# STM32H7B0x register map
File version: 1.3
CPU: CM7 r0p1, little endian, MPU, FPU, 4 interrupt priority bits
Registers are 32-bit, read-write, reset 0x0 unless marked. A register's access mark holds for its fields unless they carry their own. Offsets are from the block's base; [hi:lo] are bit positions; {n}, {i} and the like mark numbered series.

## RCC (part 3 of 3) — Reset and clock control
Base 0x58024400
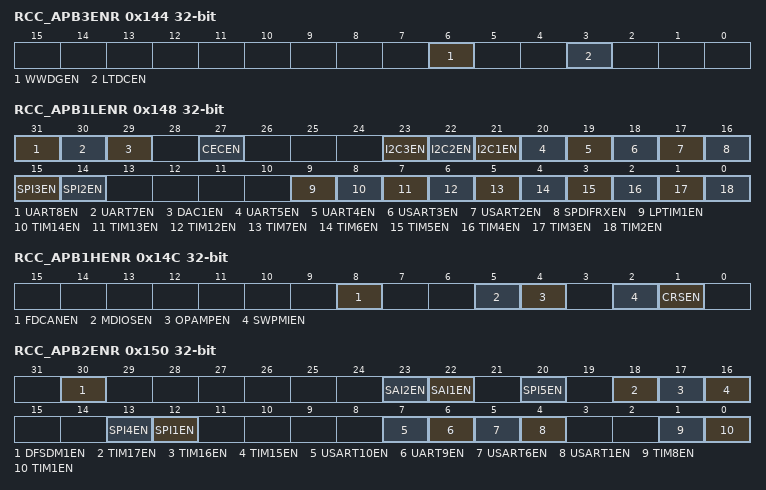
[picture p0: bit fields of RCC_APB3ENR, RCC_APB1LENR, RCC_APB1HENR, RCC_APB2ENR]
0x144 RCC_APB3ENR
  [6] WWDGEN — WWDG clock enable Set by software, and reset by hardware when a system reset occurs. Note that in order to work properly, before enabling the WWDG, the bit WW1RSC must be set to 1.
    0=WWDG peripheral clock disable (default after reset); 1=WWDG peripheral clock enabled
  [3] LTDCEN — LTDC clock enable Provides the clock (ltdc_pclk, ltdc_aclk, ltdc_ker_ck) to the LTDC block. Set and reset by software.
    0=LTDC peripheral clock disabled (default after reset); 1=LTDC peripheral clock provided to the LTDC block
0x148 RCC_APB1LENR
  [31] UART8EN — UART8 peripheral clocks enable Set and reset by software. The peripheral clocks of the UART8 are the kernel clock selected by USART234578SEL and provided to usart_ker_ck input, and the rcc_pclk1 bus interface clock.
    0=UART8 peripheral clocks disabled (default after reset); 1=UART8 peripheral clocks enabled
  [30] UART7EN — UART7 peripheral clocks enable Set and reset by software. The peripheral clocks of the UART7 are the kernel clock selected by USART234578SEL and provided to usart_ker_ck input, and the rcc_pclk1 bus interface clock.
    0=UART7 peripheral clocks disabled (default after reset); 1=UART7 peripheral clocks enabled
  [29] DAC1EN — DAC1 (containing two converters) peripheral clock enable Set and reset by software.
    0=DAC1 peripheral clock disabled (default after reset); 1=DAC1 peripheral clock enabled
  [27] CECEN — HDMI-CEC peripheral clock enable Set and reset by software. The peripheral clocks of the HDMI-CEC are the kernel clock selected by CECSEL and provided to cec_ker_ck input, and the rcc_pclk1 bus interface clock.
    0=HDMI-CEC peripheral clock disabled (default after reset); 1=HDMI-CEC peripheral clock enabled
  [23] I2C3EN — I2C3 peripheral clocks enable Set and reset by software. The peripheral clocks of the I2C3 are the kernel clock selected by I2C123SEL and provided to i2C_ker_ck input, and the rcc_pclk1 bus interface clock.
    0=I2C3 peripheral clocks disabled (default after reset); 1=I2C3 peripheral clocks enabled
  [22] I2C2EN — I2C2 peripheral clocks enable Set and reset by software. The peripheral clocks of the I2C2 are the kernel clock selected by I2C123SEL and provided to i2C_ker_ck input, and the rcc_pclk1 bus interface clock.
    0=I2C2 peripheral clocks disabled (default after reset); 1=I2C2 peripheral clocks enabled
  [21] I2C1EN — I2C1 peripheral clocks enable Set and reset by software. The peripheral clocks of the I2C1 are the kernel clock selected by I2C123SEL and provided to i2C_ker_ck input, and the rcc_pclk1 bus interface clock.
    0=I2C1 peripheral clocks disabled (default after reset); 1=I2C1 peripheral clocks enabled
  [20] UART5EN — UART5 peripheral clocks enable Set and reset by software. The peripheral clocks of the UART5 are the kernel clock selected by USART234578SEL and provided to usart_ker_ck input, and the rcc_pclk1 bus interface clock.
    0=UART5 peripheral clocks disabled (default after reset); 1=UART5 peripheral clocks enabled
  [19] UART4EN — UART4 peripheral clocks enable Set and reset by software. The peripheral clocks of the UART4 are the kernel clock selected by USART234578SEL and provided to usart_ker_ck input, and the rcc_pclk1 bus interface clock.
    0=UART4 peripheral clocks disabled (default after reset); 1=UART4 peripheral clocks enabled
  [18] USART3EN — USART3 peripheral clocks enable Set and reset by software. The peripheral clocks of the USART3 are the kernel clock selected by USART234578SEL and provided to usart_ker_ck input, and the rcc_pclk1 bus interface clock.
    0=USART3 peripheral clocks disabled (default after reset); 1=USART3 peripheral clocks enabled
  [17] USART2EN — USART2peripheral clocks enable Set and reset by software. The peripheral clocks of the USART2 are the kernel clock selected by USART234578SEL and provided to usart_ker_ck input, and the rcc_pclk1 bus interface clock.
    0=USART2 peripheral clocks disabled (default after reset); 1=USART2 peripheral clocks enabled
  [16] SPDIFRXEN — SPDIFRX peripheral clocks enable Set and reset by software. The peripheral clocks of the SPDIFRX are the kernel clock selected by SPDIFRXSEL and provided to spdifrx_ker_ck input, and the rcc_pclk1 bus interface clock.
    0=SPDIFRX peripheral clocks disabled (default after reset); 1=SPDIFRX peripheral clocks enabled
  [15] SPI3EN — SPI3 peripheral clocks enable Set and reset by software. The peripheral clocks of the SPI3 are the kernel clock selected by I2S123SRC and provided to spi_ker_ck input, and the rcc_pclk1 bus interface clock.
    0=SPI3 peripheral clocks disabled (default after reset); 1=SPI3 peripheral clocks enabled
  [14] SPI2EN — SPI2 peripheral clocks enable Set and reset by software. The peripheral clocks of the SPI2 are the kernel clock selected by I2S123SRC and provided to spi_ker_ck input, and the rcc_pclk1 bus interface clock.
    0=SPI2 peripheral clocks disabled (default after reset); 1=SPI2 peripheral clocks enabled
  [9] LPTIM1EN — LPTIM1 peripheral clocks enable Set and reset by software. The peripheral clocks of the LPTIM1 are the kernel clock selected by LPTIM1SEL and provided to lptim_ker_ck input, and the rcc_pclk1 bus interface clock.
    0=LPTIM1 peripheral clocks disabled (default after reset); 1=LPTIM1 peripheral clocks enabled
  [8] TIM14EN — TIM14 peripheral clock enable Set and reset by software.
    0=TIM14 peripheral clock disabled (default after reset); 1=TIM14 peripheral clock enabled
  [7] TIM13EN — TIM13 peripheral clock enable Set and reset by software.
    0=TIM13 peripheral clock disabled (default after reset); 1=TIM13 peripheral clock enabled
  [6] TIM12EN — TIM12 peripheral clock enable Set and reset by software.
    0=TIM12 peripheral clock disabled (default after reset); 1=TIM12 peripheral clock enabled
  [5] TIM7EN — TIM7 peripheral clock enable Set and reset by software.
    0=TIM7 peripheral clock disabled (default after reset); 1=TIM7 peripheral clock enabled
  [4] TIM6EN — TIM6 peripheral clock enable Set and reset by software.
    0=TIM6 peripheral clock disabled (default after reset); 1=TIM6 peripheral clock enabled
  [3] TIM5EN — TIM5 peripheral clock enable Set and reset by software.
    0=TIM5 peripheral clock disabled (default after reset); 1=TIM5 peripheral clock enabled
  [2] TIM4EN — TIM4 peripheral clock enable Set and reset by software.
    0=TIM4 peripheral clock disable (default after reset); 1=TIM4 peripheral clock enabled
  [1] TIM3EN — TIM3 peripheral clock enable Set and reset by software.
    0=TIM3 peripheral clock disabled (default after reset); 1=TIM3 peripheral clock enabled
  [0] TIM2EN — TIM2 peripheral clock enable Set and reset by software.
    0=TIM2 peripheral clock disabled (default after reset); 1=TIM2 peripheral clock enabled
0x14C RCC_APB1HENR
  [8] FDCANEN — FDCAN peripheral clocks enable Set and reset by software. The peripheral clocks of the FDCAN are the kernel clock selected by FDCANSEL and provided to fdcan_ker_ck input, and the rcc_pclk1 bus interface clock.
    0=FDCAN peripheral clocks disabled (default after reset); 1=FDCAN peripheral clocks enabled:
  [5] MDIOSEN — MDIOS peripheral clock enable Set and reset by software.
    0=MDIOS peripheral clock disabled (default after reset); 1=MDIOS peripheral clock enabled
  [4] OPAMPEN — OPAMP peripheral clock enable Set and reset by software.
    0=OPAMP peripheral clock disabled (default after reset); 1=OPAMP peripheral clock enabled
  [2] SWPMIEN — SWPMI peripheral clocks enable Set and reset by software.
    0=SWPMI peripheral clocks disabled (default after reset); 1=SWPMI peripheral clocks enabled:
  [1] CRSEN — clock recovery system peripheral clock enable Set and reset by software.
    0=CRS peripheral clock disabled (default after reset); 1=CRS peripheral clock enabled
0x150 RCC_APB2ENR
  [30] DFSDM1EN — DFSDM1 peripheral clocks enable Set and reset by software. DFSDM1 peripheral clocks are the kernel clocks selected by SAI1SEL and DFSDM1SEL and provided to Aclk and clk inputs respectively,
    0=DFSDM1 peripheral clocks disabled (default after reset); 1=DFSDM1 peripheral clocks enabled
  [23] SAI2EN — SAI2 peripheral clocks enable Set and reset by software. The peripheral clocks of the SAI2 are the kernel clock selected by SAI2SEL and provided to sai_a_ker_ck and sai_b_ker_ck inputs, and the rcc_pclk2 bus interface clock.
    0=SAI2 peripheral clocks disabled (default after reset); 1=SAI2 peripheral clocks enabled
  [22] SAI1EN — SAI1 peripheral clocks enable Set and reset by software. The peripheral clocks of the SAI1 are: the kernel clock selected by SAI1SEL and provided to sai_a_ker_ck and sai_b_ker_ck inputs, and the rcc_pclk2 bus interface clock.
    0=SAI1 peripheral clocks disabled (default after reset); 1=SAI1 peripheral clocks enabled:
  [20] SPI5EN — SPI5 peripheral clocks enable Set and reset by software. The peripheral clocks of the SPI5 are the kernel clock selected by SPI45SEL and provided to spi_ker_ck input, and the rcc_pclk2 bus interface clock.
    0=SPI5 peripheral clocks disabled (default after reset); 1=SPI5 peripheral clocks enabled:
  [18] TIM17EN — TIM17 peripheral clock enable Set and reset by software.
    0=TIM17 peripheral clock disabled (default after reset); 1=TIM17 peripheral clock enabled
  [17] TIM16EN — TIM16 peripheral clock enable Set and reset by software.
    0=TIM16 peripheral clock disabled (default after reset); 1=TIM16 peripheral clock enabled
  [16] TIM15EN — TIM15 peripheral clock enable Set and reset by software.
    0=TIM15 peripheral clock disabled (default after reset); 1=TIM15 peripheral clock enabled
  [13] SPI4EN — SPI4 Peripheral Clocks Enable Set and reset by software. The peripheral clocks of the SPI4 are: the kernel clock selected by SPI45SEL and provided to spi_ker_ck input, and the rcc_pclk2 bus interface clock.
    0=SPI4 peripheral clocks disabled (default after reset); 1=SPI4 peripheral clocks enabled:
  [12] SPI1EN — SPI1 Peripheral Clocks Enable Set and reset by software. The peripheral clocks of the SPI1 are: the kernel clock selected by I2S123SRC and provided to spi_ker_ck input, and the rcc_pclk2 bus interface clock.
    0=SPI1 peripheral clocks disabled (default after reset); 1=SPI1 peripheral clocks enabled:
  [7] USART10EN — USART10 peripheral clocks enable Set and reset by software. The peripheral clocks of the USART10 are the kernel clock selected by USART16910SEL and provided to UCKL input, and the rcc_pclk2 bus interface clock.
    0=USART10 peripheral clocks disabled (default after reset); 1=USART10 peripheral clocks enabled:
  [6] UART9EN — UART9 peripheral clocks enable Set and reset by software. The peripheral clocks of the UART9 are the kernel clock selected by USART16910SEL and provided to UCKL input, and the rcc_pclk2 bus interface clock.
    0=UART9 peripheral clocks disabled (default after reset); 1=UART9 peripheral clocks enabled:
  [5] USART6EN — USART6 peripheral clocks enable Set and reset by software. The peripheral clocks of the USART6 are the kernel clock selected by USART16910SEL and provided to UCKL input, and the rcc_pclk2 bus interface clock.
    0=USART6 peripheral clocks disabled (default after reset); 1=USART6 peripheral clocks enabled:
  [4] USART1EN — USART1 peripheral clocks enable Set and reset by software. The peripheral clocks of the USART1 are the kernel clock selected by USART16910SEL and provided to UCKL input, and the rcc_pclk2 bus interface clock.
    0=USART1 peripheral clocks disabled (default after reset); 1=USART1 peripheral clocks enabled:
  [1] TIM8EN — TIM8 peripheral clock enable Set and reset by software.
    0=TIM8 peripheral clock disabled (default after reset); 1=TIM8 peripheral clock enabled
  [0] TIM1EN — TIM1 peripheral clock enable Set and reset by software.
    0=TIM1 peripheral clock disabled (default after reset); 1=TIM1 peripheral clock enabled
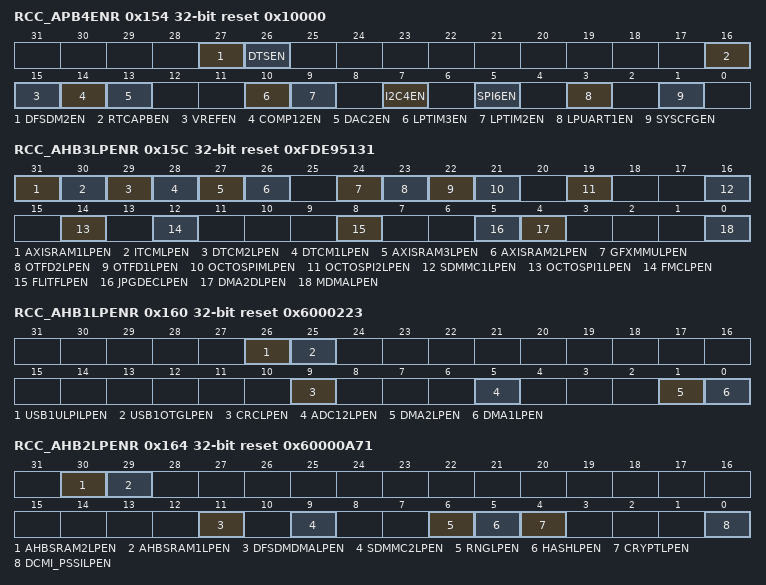
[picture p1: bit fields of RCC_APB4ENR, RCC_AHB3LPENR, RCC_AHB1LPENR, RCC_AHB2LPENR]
0x154 RCC_APB4ENR reset 0x10000
  [27] DFSDM2EN — DFSDM2peripheral clock enable Set and reset by software.
    0=DFSDM2peripheral peripheral clock disabled (default after reset); 1=DFSDM2peripheral peripheral clock enabled
  [26] DTSEN — Digital temperature sensor peripheral clock enable Set and reset by software.
    0=DTS peripheral clock disabled (default after reset); 1=DTS peripheral clock enabled
  [16] RTCAPBEN — RTC APB clock enable Set and reset by software.
    0=The register clock interface of the RTC (APB) is disabled; 1=The register clock interface of the RTC (APB) is enabled (default after reset)
  [15] VREFEN — VREF peripheral clock enable Set and reset by software.
    0=VREF peripheral clock disabled (default after reset); 1=VREF peripheral clock enabled
  [14] COMP12EN — COMP1 and 2 peripheral clock enable Set and reset by software.
    0=COMP1 and 2 peripheral clock disabled (default after reset); 1=COMP1 and 2 peripheral clock enabled
  [13] DAC2EN — DAC2 (containing one converter) peripheral clock enable Set and reset by software.
    0=DAC2 peripheral clock disabled (default after reset); 1=DAC2 peripheral clock enabled
  [10] LPTIM3EN — LPTIM3 peripheral clocks enable Set and reset by software. The peripheral clocks of the LPTIM3 are the kernel clock selected by LPTIM345SEL and provided to lptim_ker_ck input, and the rcc_pclk4 bus interface clock.
    0=LPTIM3 peripheral clocks disabled (default after reset); 1=LPTIM3 peripheral clocks enabled
  [9] LPTIM2EN — LPTIM2 peripheral clocks enable Set and reset by software. The peripheral clocks of the LPTIM2 are the kernel clock selected by LPTIM2SEL and provided to lptim_ker_ck input, and the rcc_pclk4 bus interface clock.
    0=LPTIM2 peripheral clocks disabled (default after reset); 1=LPTIM2 peripheral clocks enabled
  [7] I2C4EN — I2C4 peripheral clocks enable Set and reset by software. The peripheral clocks of the I2C4 are the kernel clock selected by I2C4SEL and provided to i2C_ker_ck input, and the rcc_pclk4 bus interface clock.
    0=I2C4 peripheral clocks disabled (default after reset); 1=I2C4 peripheral clocks enabled
  [5] SPI6EN — SPI6 peripheral clocks enable Set and reset by software. The peripheral clocks of the SPI6 are the kernel clock selected by SPI6SEL and provided to spi_ker_ck input, and the rcc_pclk4 bus interface clock.
    0=SPI6 peripheral clocks disabled (default after reset); 1=SPI6 peripheral clocks enabled
  [3] LPUART1EN — LPUART1 peripheral clocks enable Set and reset by software. The peripheral clocks of the LPUART1 are the kernel clock selected by LPUART1SEL and provided to lpuart_ker_ck input, and the rcc_pclk4 bus interface clock.
    0=LPUART1 peripheral clocks disabled (default after reset); 1=LPUART1 peripheral clocks enabled
  [1] SYSCFGEN — SYSCFG peripheral clock enable Set and reset by software.
    0=SYSCFG peripheral clock disabled (default after reset); 1=SYSCFG peripheral clock enabled
0x15C RCC_AHB3LPENR reset 0xFDE95131
  [31] AXISRAM1LPEN — AXISRAM1 block clock enable during CSleep mode Set and reset by software.
    0=AXISRAM1 interface clock disabled during CSleep mode; 1=AXISRAM1 interface clock enabled during CSleep mode (default after reset)
  [30] ITCMLPEN — ITCM block clock enable during CSleep mode Set and reset by software.
    0=ITCM interface clock disabled during CSleep mode; 1=ITCM interface clock enabled during CSleep mode (default after reset)
  [29] DTCM2LPEN — DTCM2 block clock enable during CSleep mode Set and reset by software.
    0=DTCM2 interface clock disabled during CSleep mode; 1=DTCM2 interface clock enabled during CSleep mode (default after reset)
  [28] DTCM1LPEN — DTCM1 block clock enable during CSleep mode Set and reset by software.
    0=DTCM1 interface clock disabled during CSleep mode; 1=DTCM1 interface clock enabled during CSleep mode (default after reset)
  [27] AXISRAM3LPEN — AXISRAM3 block clock enable during CSleep mode Set and reset by software.
    0=AXISRAM3 interface clock disabled during CSleep mode; 1=AXISRAM3 interface clock enabled during CSleep mode (default after reset)
  [26] AXISRAM2LPEN — AXISRAM2 block clock enable during CSleep mode Set and reset by software.
    0=AXISRAM2 interface clock disabled during CSleep mode; 1=AXISRAM2 interface clock enabled during CSleep mode (default after reset)
  [24] GFXMMULPEN — GFXMMU block clock enable during CSleep mode Set and reset by software.
    0=GFXMMU interface clock disabled during CSleep mode; 1=GFXMMU interface clock enabled during CSleep mode (default after reset)
  [23] OTFD2LPEN — OTFD2 block clock enable during CSleep mode Set and reset by software.
    0=OTFD2 interface clock disabled during CSleep mode; 1=OTFD2 interface clock enabled during CSleep mode (default after reset)
  [22] OTFD1LPEN — OTFD1 block clock enable during CSleep mode Set and reset by software.
    0=OTFD1 interface clock disabled during CSleep mode; 1=OTFD1 interface clock enabled during CSleep mode (default after reset)
  [21] OCTOSPIMLPEN — OCTOSPIM block clock enable during CSleep mode Set and reset by software.
    0=OCTOSPIM interface clock disabled during CSleep mode; 1=OCTOSPIM interface clock enabled during CSleep mode (default after reset)
  [19] OCTOSPI2LPEN — OCTOSPI2 and OCTOSPI2 delay clock enable during CSleep mode Set and reset by software.
    0=OCTOSPI2 and OCTOSPI2 delay clock disabled during CSleep mode; 1=OCTOSPI2 and OCTOSPI2 delay clock enabled during CSleep mode (default after reset)
  [16] SDMMC1LPEN — SDMMC1 and SDMMC1 delay clock enable during CSleep mode Set and reset by software.
    0=SDMMC1 and SDMMC1 delay clock disabled during CSleep mode; 1=SDMMC1 and SDMMC1 delay clock enabled during CSleep mode (default after reset)
  [14] OCTOSPI1LPEN — OCTOSPI1 and OCTOSPI1 delay clock enable during CSleep mode Set and reset by software.
    0=OCTOSPI1 and OCTOSPI1 delay clock disabled during CSleep mode; 1=OCTOSPI1 and OCTOSPI1 delay clock enabled during CSleep mode (default after reset)
  [12] FMCLPEN — FMC peripheral clocks enable during CSleep mode Set and reset by software. The peripheral clocks of the FMC are the kernel clock selected by FMCSEL and provided to fmc_ker_ck input, and the rcc_hclk3 bus interface clock.
    0=FMC peripheral clocks disabled during CSleep mode; 1=FMC peripheral clocks enabled during CSleep mode (default after reset):
  [8] FLITFLPEN — FLITF clock enable during CSleep mode Set and reset by software.
    0=FLITF clock disabled during CSleep mode; 1=FLITF clock enabled during CSleep mode (default after reset)
  [5] JPGDECLPEN — JPGDEC clock enable during CSleep mode Set and reset by software.
    0=JPGDEC peripheral clock disabled during CSleep mode; 1=JPGDEC peripheral clock enabled during CSleep mode (default after reset)
  [4] DMA2DLPEN — DMA2D clock enable during CSleep mode Set and reset by software.
    0=DMA2D peripheral clock disabled during CSleep mode; 1=DMA2D peripheral clock enabled during CSleep mode (default after reset)
  [0] MDMALPEN — MDMA clock enable during CSleep mode Set and reset by software.
    0=MDMA peripheral clock disabled during CSleep mode; 1=MDMA peripheral clock enabled during CSleep mode (default after reset)
0x160 RCC_AHB1LPENR reset 0x6000223
  [26] USB1ULPILPEN — USB_PHY1 clock enable during CSleep mode Set and reset by software.
    0=USB_PHY1 peripheral clock disabled during CSleep mode; 1=USB_PHY1 peripheral clock enabled during CSleep mode (default after reset)
  [25] USB1OTGLPEN — USB1OTG peripheral clock enable during CSleep mode Set and reset by software. The peripheral clocks of the USB1OTG are the kernel clock selected by USBSEL and the rcc_hclk1 bus interface clock.
    0=USB1OTG peripheral clock disabled during CSleep mode; 1=USB1OTG peripheral clock enabled during CSleep mode (default after reset)
  [9] CRCLPEN — CRC peripheral clock enable during CSleep mode Set and reset by software.
    0=CRC peripheral clock disabled during CSleep mode; 1=CRC peripheral clock enabled during CSleep mode (default after reset)
  [5] ADC12LPEN — ADC1 and 2 peripheral clocks enable during CSleep mode Set and reset by software. The peripheral clocks of the ADC1 and 2 are the kernel clock selected by ADCSEL and provided to adc_ker_ck input, and the rcc_hclk1 bus interface clock.
    0=ADC1 and 2 peripheral clocks disabled during CSleep mode; 1=ADC1 and 2 peripheral clocks enabled during CSleep mode (default after reset)
  [1] DMA2LPEN — DMA2 clock enable during CSleep mode Set and reset by software.
    0=DMA2 clock disabled during CSleep mode; 1=DMA2 clock enabled during CSleep mode (default after reset)
  [0] DMA1LPEN — DMA1 clock enable during CSleep mode Set and reset by software.
    0=DMA1 clock disabled during CSleep mode; 1=DMA1 clock enabled during CSleep mode (default after reset)
0x164 RCC_AHB2LPENR reset 0x60000A71
  [30] AHBSRAM2LPEN — AHBSRAM2 clock enable during CSleep mode Set and reset by software.
    0=AHBSRAM2 clock disabled during CSleep mode; 1=AHBSRAM2 clock enabled during CSleep mode (default after reset)
  [29] AHBSRAM1LPEN — AHBSRAM1 clock enable during CSleep mode Set and reset by software.
    0=AHBSRAM1 clock disabled during CSleep mode; 1=AHBSRAM1 clock enabled during CSleep mode (default after reset)
  [11] DFSDMDMALPEN — DFSDMDMA clock enable during CSleep mode Set and reset by software.
    0=DFSDMDMA clock disabled during CSleep mode; 1=DFSDMDMA clock enabled during CSleep mode (default after reset)
  [9] SDMMC2LPEN — SDMMC2 and SDMMC2 delay clock enable during CSleep mode Set and reset by software.
    0=SDMMC2 and SDMMC2 delay clock disabled during CSleep mode; 1=SDMMC2 and SDMMC2 delay clock enabled during CSleep mode (default after reset)
  [6] RNGLPEN — RNG peripheral clock enable during CSleep mode Set and reset by software. The peripheral clocks of the RNG are the kernel clock selected by RNGSEL and provided to rng_clk input, and the rcc_hclk2 bus interface clock.
    0=RNG peripheral clocks disabled during CSleep mode; 1=RNG peripheral clock enabled during CSleep mode (default after reset)
  [5] HASHLPEN — HASH peripheral clock enable during CSleep mode Set and reset by software.
    0=HASH peripheral clock disabled during CSleep mode; 1=HASH peripheral clock enabled during CSleep mode (default after reset)
  [4] CRYPTLPEN — CRYPT peripheral clock enable during CSleep mode Set and reset by software.
    0=CRYPT peripheral clock disabled during CSleep mode; 1=CRYPT peripheral clock enabled during CSleep mode (default after reset)
  [0] DCMI_PSSILPEN — digital camera interface peripheral clock enable during CSleep mode (DCMI or PSSI depending which IP is active) Set and reset by software.
    0=DCMI/PSSI peripheral clock disabled during CSleep mode; 1=DCMI/PSSI peripheral clock enabled during CSleep mode (default after reset)
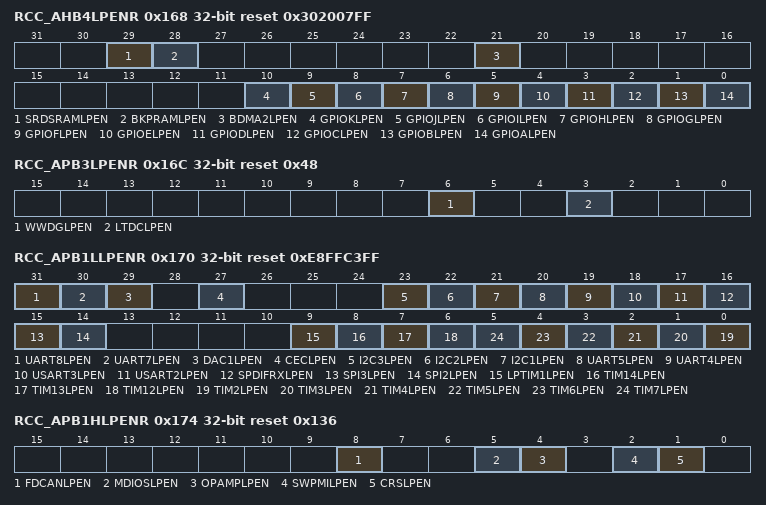
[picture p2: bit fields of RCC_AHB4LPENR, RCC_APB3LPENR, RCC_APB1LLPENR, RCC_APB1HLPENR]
0x168 RCC_AHB4LPENR reset 0x302007FF
  [29] SRDSRAMLPEN — SmartRun domain SRAM clock enable during CSleep mode Set and reset by software.
    0=SRDSRAM clock disabled during CSleep mode; 1=SRDSRAM clock enabled during CSleep mode (default after reset)
  [28] BKPRAMLPEN — Backup RAM clock enable during CSleep mode Set and reset by software.
    0=Backup RAM clock disabled during CSleep mode; 1=Backup RAM clock enabled during CSleep mode (default after reset)
  [21] BDMA2LPEN — SmartRun domain DMA and DMAMUX clock enable during CSleep mode Set and reset by software.
    0=BDMA2 and DMAMUX2 clock disabled during CSleep mode; 1=BDMA2 and DMAMUX2 clock enabled during CSleep mode (default after reset)
  [10] GPIOKLPEN — GPIOK peripheral clock enable during CSleep mode Set and reset by software.
    0=GPIOK peripheral clock disabled during CSleep mode; 1=GPIOK peripheral clock enabled during CSleep mode (default after reset)
  [9] GPIOJLPEN — GPIOJ peripheral clock enable during CSleep mode Set and reset by software.
    0=GPIOJ peripheral clock disabled during CSleep mode; 1=GPIOJ peripheral clock enabled during CSleep mode (default after reset)
  [8] GPIOILPEN — GPIOI peripheral clock enable during CSleep mode Set and reset by software.
    0=GPIOI peripheral clock disabled during CSleep mode; 1=GPIOI peripheral clock enabled during CSleep mode (default after reset)
  [7] GPIOHLPEN — GPIOH peripheral clock enable during CSleep mode Set and reset by software.
    0=GPIOH peripheral clock disabled during CSleep mode; 1=GPIOH peripheral clock enabled during CSleep mode (default after reset)
  [6] GPIOGLPEN — GPIOG peripheral clock enable during CSleep mode Set and reset by software.
    0=GPIOG peripheral clock disabled during CSleep mode; 1=GPIOG peripheral clock enabled during CSleep mode (default after reset)
  [5] GPIOFLPEN — GPIOF peripheral clock enable during CSleep mode Set and reset by software.
    0=GPIOF peripheral clock disabled during CSleep mode; 1=GPIOF peripheral clock enabled during CSleep mode (default after reset)
  [4] GPIOELPEN — GPIOE peripheral clock enable during CSleep mode Set and reset by software.
    0=GPIOE peripheral clock disabled during CSleep mode; 1=GPIOE peripheral clock enabled during CSleep mode (default after reset)
  [3] GPIODLPEN — GPIOD peripheral clock enable during CSleep mode Set and reset by software.
    0=GPIOD peripheral clock disabled during CSleep mode; 1=GPIOD peripheral clock enabled during CSleep mode (default after reset)
  [2] GPIOCLPEN — GPIOC peripheral clock enable during CSleep mode Set and reset by software.
    0=GPIOC peripheral clock disabled during CSleep mode; 1=GPIOC peripheral clock enabled during CSleep mode (default after reset)
  [1] GPIOBLPEN — GPIOB peripheral clock enable during CSleep mode Set and reset by software.
    0=GPIOB peripheral clock disabled during CSleep mode; 1=GPIOB peripheral clock enabled during CSleep mode (default after reset)
  [0] GPIOALPEN — GPIOA peripheral clock enable during CSleep mode Set and reset by software.
    0=GPIOA peripheral clock disabled during CSleep mode; 1=GPIOA peripheral clock enabled during CSleep mode (default after reset)
0x16C RCC_APB3LPENR reset 0x48
  [6] WWDGLPEN — WWDG clock enable during CSleep mode Set and reset by software.
    0=WWDG clock disable during CSleep mode; 1=WWDG clock enabled during CSleep mode (default after reset)
  [3] LTDCLPEN — LTDC peripheral clock enable during CSleep mode Set and reset by software. The LTDC peripheral clocks are the kernel clock provided to ltdc_ker_ck input and the rcc_pclk3 bus interface clock.
    0=LTDC clock disabled during CSleep mode; 1=LTDC clock provided to the LTDC during CSleep mode (default after reset)
0x170 RCC_APB1LLPENR reset 0xE8FFC3FF
  [31] UART8LPEN — UART8 peripheral clocks enable during CSleep mode Set and reset by software. The peripheral clocks of the UART8 are the kernel clock selected by USART234578SEL and provided to usart_ker_ck input, and the rcc_pclk1 bus interface clock.
    0=UART8 peripheral clocks disabled during CSleep mode; 1=UART8 peripheral clocks enabled during CSleep mode (default after reset):
  [30] UART7LPEN — UART7 peripheral clocks enable during CSleep mode Set and reset by software. The peripheral clocks of the UART7 are the kernel clock selected by USART234578SEL and provided to usart_ker_ck input, and the rcc_pclk1 bus interface clock.
    0=UART7 peripheral clocks disabled during CSleep mode; 1=UART7 peripheral clocks enabled during CSleep mode (default after reset):
  [29] DAC1LPEN — DAC1 (containing two converters) peripheral clock enable during CSleep mode Set and reset by software.
    0=DAC1 peripheral clock disabled during CSleep mode; 1=DAC1 peripheral clock enabled during CSleep mode (default after reset)
  [27] CECLPEN — HDMI-CEC peripheral clocks enable during CSleep mode Set and reset by software. The peripheral clocks of the HDMI-CEC are the kernel clock selected by CECSEL and provided to cec_ker_ck input, and the rcc_pclk1 bus interface clock.
    0=HDMI-CEC peripheral clocks disabled during CSleep mode; 1=HDMI-CEC peripheral clocks enabled during CSleep mode (default after reset)
  [23] I2C3LPEN — I2C3 peripheral clocks enable during CSleep mode Set and reset by software. The peripheral clocks of the I2C3 are the kernel clock selected by I2C123SEL and provided to i2C_ker_ck input, and the rcc_pclk1 bus interface clock.
    0=I2C3 peripheral clocks disabled during CSleep mode; 1=I2C3 peripheral clocks enabled during CSleep mode (default after reset):
  [22] I2C2LPEN — I2C2 peripheral clocks enable during CSleep mode Set and reset by software. The peripheral clocks of the I2C2 are the kernel clock selected by I2C123SEL and provided to i2C_ker_ck input, and the rcc_pclk1 bus interface clock.
    0=I2C2 peripheral clocks disabled during CSleep mode; 1=I2C2 peripheral clocks enabled during CSleep mode (default after reset):
  [21] I2C1LPEN — I2C1 peripheral clocks enable during CSleep mode Set and reset by software. The peripheral clocks of the I2C1 are the kernel clock selected by I2C123SEL and provided to i2C_ker_ck input, and the rcc_pclk1 bus interface clock.
    0=I2C1 peripheral clocks disabled during CSleep mode; 1=I2C1 peripheral clocks enabled during CSleep mode (default after reset):
  [20] UART5LPEN — UART5 peripheral clocks enable during CSleep mode Set and reset by software. The peripheral clocks of the UART5 are the kernel clock selected by USART234578SEL and provided to usart_ker_ck input, and the rcc_pclk1 bus interface clock.
    0=UART5 peripheral clocks disabled during CSleep mode; 1=UART5 peripheral clocks enabled during CSleep mode (default after reset)
  [19] UART4LPEN — UART4 peripheral clocks enable during CSleep mode Set and reset by software. The peripheral clocks of the UART4 are the kernel clock selected by USART234578SEL and provided to usart_ker_ck input, and the rcc_pclk1 bus interface clock.
    0=UART4 peripheral clocks disabled during CSleep mode; 1=UART4 peripheral clocks enabled during CSleep mode (default after reset)
  [18] USART3LPEN — USART3 peripheral clocks enable during CSleep mode Set and reset by software. The peripheral clocks of the USART3 are the kernel clock selected by USART234578SEL and provided to usart_ker_ck input, and the rcc_pclk1 bus interface clock.
    0=USART3 peripheral clocks disabled during CSleep mode; 1=USART3 peripheral clocks enabled during CSleep mode (default after reset):
  [17] USART2LPEN — USART2 peripheral clocks enable during CSleep mode Set and reset by software. The peripheral clocks of the USART2 are the kernel clock selected by USART234578SEL and provided to usart_ker_ck input, and the rcc_pclk1 bus interface clock.
    0=USART2 peripheral clocks disabled during CSleep mode; 1=USART2 peripheral clocks enabled during CSleep mode (default after reset)
  [16] SPDIFRXLPEN — SPDIFRX peripheral clocks enable during CSleep mode Set and reset by software. The peripheral clocks of the SPDIFRX are: the kernel clock selected by SPDIFRXSEL and provided to spdifrx_ker_ck input, and the rcc_pclk1 bus interface clock.
    0=SPDIFRX peripheral clocks disabled during CSleep mode; 1=SPDIFRX peripheral clocks enabled during CSleep mode (default after reset)
  [15] SPI3LPEN — SPI3 peripheral clocks enable during CSleep mode Set and reset by software. The peripheral clocks of the SPI3 are the kernel clock selected by I2S123SRC and provided to spi_ker_ck input, and the rcc_pclk1 bus interface clock.
    0=SPI3 peripheral clocks disabled during CSleep mode; 1=SPI3 peripheral clocks enabled during CSleep mode (default after reset)
  [14] SPI2LPEN — SPI2 peripheral clocks enable during CSleep mode Set and reset by software. The peripheral clocks of the SPI2 are the kernel clock selected by I2S123SRC and provided to spi_ker_ck input, and the rcc_pclk1 bus interface clock.
    0=SPI2 peripheral clocks disabled during CSleep mode; 1=SPI2 peripheral clocks enabled during CSleep mode (default after reset)
  [9] LPTIM1LPEN — LPTIM1 peripheral clocks enable during CSleep mode Set and reset by software. The peripheral clocks of the LPTIM1 are the kernel clock selected by LPTIM1SEL and provided to lptim_ker_ck input, and the rcc_pclk1 bus interface clock.
    0=LPTIM1 peripheral clocks disabled during CSleep mode; 1=LPTIM1 peripheral clocks enabled during CSleep mode (default after reset)
  [8] TIM14LPEN — TIM14 peripheral clock enable during CSleep mode Set and reset by software.
    0=TIM14 peripheral clock disabled during CSleep mode; 1=TIM14 peripheral clock enabled during CSleep mode (default after reset)
  [7] TIM13LPEN — TIM13 peripheral clock enable during CSleep mode Set and reset by software.
    0=TIM13 peripheral clock disabled during CSleep mode; 1=TIM13 peripheral clock enabled during CSleep mode (default after reset)
  [6] TIM12LPEN — TIM12 peripheral clock enable during CSleep mode Set and reset by software.
    0=TIM12 peripheral clock disabled during CSleep mode; 1=TIM12 peripheral clock enabled during CSleep mode (default after reset)
  [n-2] TIM{n}LPEN (n=2..7) — TIM{n} peripheral clock enable during CSleep mode Set and reset by software.
    0=TIM{n} peripheral clock disabled during CSleep mode; 1=TIM{n} peripheral clock enabled during CSleep mode (default after reset)
0x174 RCC_APB1HLPENR reset 0x136
  [8] FDCANLPEN — FDCAN peripheral clocks enable during CSleep mode Set and reset by software. The peripheral clocks of the FDCAN are: the kernel clock selected by FDCANSEL and provided to fdcan_clk input, and the rcc_pclk1 bus interface clock.
    0=FDCAN peripheral clocks disabled during CSleep mode; 1=FDCAN peripheral clocks enabled during CSleep mode (default after reset)
  [5] MDIOSLPEN — MDIOS peripheral clock enable during CSleep mode Set and reset by software.
    0=MDIOS peripheral clock disabled during CSleep mode; 1=MDIOS peripheral clock enabled during CSleep mode (default after reset)
  [4] OPAMPLPEN — OPAMP peripheral clock enable during CSleep mode Set and reset by software.
    0=OPAMP peripheral clock disabled during CSleep mode; 1=OPAMP peripheral clock enabled during CSleep mode (default after reset)
  [2] SWPMILPEN — SWPMI peripheral clocks enable during CSleep mode Set and reset by software. The peripheral clocks of the SWPMI are the kernel clock selected by SWPMISEL and provided to swpmi_ker_ck input, and the rcc_pclk1 bus interface clock.
    0=SWPMI peripheral clocks disabled during CSleep mode; 1=SWPMI peripheral clocks enabled during CSleep mode (default after reset)
  [1] CRSLPEN — clock recovery system peripheral clock enable during CSleep mode Set and reset by software.
    0=CRS peripheral clock disabled during CSleep mode; 1=CRS peripheral clock enabled during CSleep mode (default after reset)
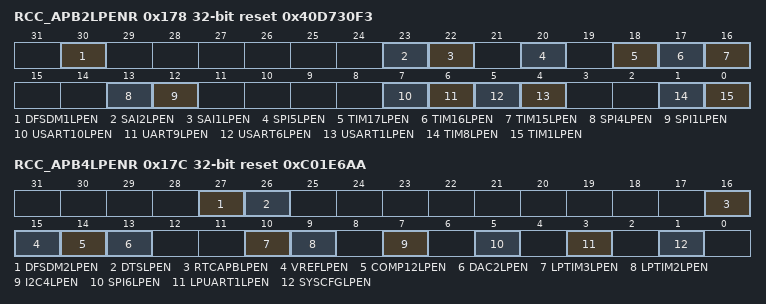
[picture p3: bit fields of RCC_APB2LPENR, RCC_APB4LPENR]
0x178 RCC_APB2LPENR reset 0x40D730F3
  [30] DFSDM1LPEN — DFSDM1 peripheral clocks enable during CSleep mode Set and reset by software. DFSDM1 peripheral clocks are the kernel clocks selected by SAI1SEL and DFSDM1SEL and provided to Aclk and clk inputs respectively, and the rcc_pclk2 bus interface clock.
    0=DFSDM1 peripheral clocks disabled during CSleep mode; 1=DFSDM1 peripheral clocks enabled during CSleep mode (default after reset)
  [23] SAI2LPEN — SAI2 peripheral clocks enable during CSleep mode Set and reset by software. The peripheral clocks of the SAI2 are the kernel clock selected by SAI23EL and provided to sai_a_ker_ck and sai_b_ker_ck inputs, and the rcc_pclk2 bus interface clock.
    0=SAI2 peripheral clocks disabled during CSleep mode; 1=SAI2 peripheral clocks enabled during CSleep mode (default after reset)
  [22] SAI1LPEN — SAI1 peripheral clocks enable during CSleep mode Set and reset by software. The peripheral clocks of the SAI1 are: the kernel clock selected by SAI1SEL and provided to sai_a_ker_ck and sai_b_ker_ck inputs, and the rcc_pclk2 bus interface clock.
    0=SAI1 peripheral clocks disabled during CSleep mode; 1=SAI1 peripheral clocks enabled during CSleep mode (default after reset)
  [20] SPI5LPEN — SPI5 peripheral clocks enable during CSleep mode Set and reset by software. The peripheral clocks of the SPI5 are the kernel clock selected by SPI45SEL and provided to spi_ker_ck input, and the rcc_pclk2 bus interface clock.
    0=SPI5 peripheral clocks disabled during CSleep mode; 1=SPI5 peripheral clocks enabled during CSleep mode (default after reset)
  [18] TIM17LPEN — TIM17 peripheral clock enable during CSleep mode Set and reset by software.
    0=TIM17 peripheral clock disabled during CSleep mode; 1=TIM17 peripheral clock enabled during CSleep mode (default after reset)
  [17] TIM16LPEN — TIM16 peripheral clock enable during CSleep mode Set and reset by software.
    0=TIM16 peripheral clock disabled during CSleep mode; 1=TIM16 peripheral clock enabled during CSleep mode (default after reset)
  [16] TIM15LPEN — TIM15 peripheral clock enable during CSleep mode Set and reset by software.
    0=TIM15 peripheral clock disabled during CSleep mode; 1=TIM15 peripheral clock enabled during CSleep mode (default after reset)
  [13] SPI4LPEN — SPI4 peripheral clock enable during CSleep mode Set and reset by software. The peripheral clocks of the SPI4 are: the kernel clock selected by SPI45SEL and provided to spi_ker_ck input, and the rcc_pclk2 bus interface clock.
    0=SPI4 peripheral clocks disabled during CSleep mode; 1=SPI4 peripheral clocks enabled during CSleep mode (default after reset)
  [12] SPI1LPEN — SPI1 peripheral clock enable during CSleep mode Set and reset by software. The peripheral clocks of the SPI1 are: the kernel clock selected by I2S123SRC and provided to spi_ker_ck input, and the rcc_pclk2 bus interface clock.
    0=SPI1 peripheral clocks disabled during CSleep mode; 1=SPI1 peripheral clocks enabled during CSleep mode (default after reset)
  [7] USART10LPEN — USART10 peripheral clock enable during CSleep mode Set and reset by software. The peripheral clocks of the USART10 are the kernel clock selected by USART16910SEL and provided to usart_ker_ck input, and the rcc_pclk2 bus interface clock.
    0=USART10 peripheral clocks disabled during CSleep mode; 1=USART10 peripheral clocks enabled during CSleep mode (default after reset)
  [6] UART9LPEN — UART9 peripheral clock enable during CSleep mode Set and reset by software. The peripheral clocks of the UART9 are the kernel clock selected by USART16910SEL and provided to usart_ker_ck input, and the rcc_pclk2 bus interface clock.
    0=UART9 peripheral clocks disabled during CSleep mode; 1=UART9 peripheral clocks enabled during CSleep mode (default after reset)
  [5] USART6LPEN — USART6 peripheral clock enable during CSleep mode Set and reset by software. The peripheral clocks of the USART6 are the kernel clock selected by USART16910SEL and provided to usart_ker_ck input, and the rcc_pclk2 bus interface clock.
    0=USART6 peripheral clocks disabled during CSleep mode; 1=USART6 peripheral clocks enabled during CSleep mode (default after reset)
  [4] USART1LPEN — USART1 peripheral clock enable during CSleep mode Set and reset by software. The peripheral clocks of the USART1 are the kernel clock selected by USART16910SEL and provided to usart_ker_ck inputs, and the rcc_pclk2 bus interface clock.
    0=USART1 peripheral clocks disabled during CSleep mode; 1=USART1 peripheral clocks enabled during CSleep mode (default after reset)
  [1] TIM8LPEN — TIM8 peripheral clock enable during CSleep mode Set and reset by software.
    0=TIM8 peripheral clock disabled during CSleep mode; 1=TIM8 peripheral clock enabled during CSleep mode (default after reset)
  [0] TIM1LPEN — TIM1 peripheral clock enable during CSleep mode Set and reset by software.
    0=TIM1 peripheral clock disabled during CSleep mode; 1=TIM1 peripheral clock enabled during CSleep mode (default after reset)
0x17C RCC_APB4LPENR reset 0xC01E6AA
  [27] DFSDM2LPEN — DFSDM2 peripheral clock enable during CSleep mode Set and reset by software.
    0=DFSDM2 peripheral clock disabled during CSleep mode; 1=DFSDM2 peripheral clock enabled during CSleep mode (default after reset)
  [26] DTSLPEN — temperature sensor peripheral clock enable during CSleep mode Set and reset by software.
    0=DTS peripheral clock disabled during CSleep mode; 1=DTS peripheral clock enabled during CSleep mode (default after reset)
  [16] RTCAPBLPEN — RTC APB clock enable during CSleep mode Set and reset by software.
    0=The register clock interface of the RTC (APB) is disabled during CSleep mode; 1=The register clock interface of the RTC (APB) is enabled during CSleep mode (default after reset)
  [15] VREFLPEN — VREF peripheral clock enable during CSleep mode Set and reset by software.
    0=VREF peripheral clock disabled during CSleep mode; 1=VREF peripheral clock enabled during CSleep mode (default after reset)
  [14] COMP12LPEN — COMP1 and 2 peripheral clock enable during CSleep mode Set and reset by software.
    0=COMP1 and 2 peripheral clock disabled during CSleep mode; 1=COMP1 and 2 peripheral clock enabled during CSleep mode (default after reset)
  [13] DAC2LPEN — DAC2 (containing one converter) peripheral clock enable during CSleep mode Set and reset by software.
    0=DAC2 peripheral clock disabled during CSleep mode; 1=DAC2 peripheral clock enabled during CSleep mode (default after reset)
  [10] LPTIM3LPEN — LPTIM3 peripheral clocks enable during CSleep mode Set and reset by software. The peripheral clocks of the LPTIM3 are the kernel clock selected by LPTIM345SEL and provided to lptim_ker_ck input, and the rcc_pclk4 bus interface clock.
    0=LPTIM3 peripheral clocks disabled during CSleep mode; 1=LPTIM3 peripheral clocks enabled during CSleep mode (default after reset)
  [9] LPTIM2LPEN — LPTIM2 peripheral clocks enable during CSleep mode Set and reset by software. The peripheral clocks of the LPTIM2 are the kernel clock selected by LPTIM2SEL and provided to lptim_ker_ck input, and the rcc_pclk4 bus interface clock.
    0=LPTIM2 peripheral clocks disabled during CSleep mode; 1=LPTIM2 peripheral clocks enabled during CSleep mode (default after reset)
  [7] I2C4LPEN — I2C4 peripheral clocks enable during CSleep mode Set and reset by software. The peripheral clocks of the I2C4 are the kernel clock selected by I2C4SEL and provided to i2C_ker_ck input, and the rcc_pclk4 bus interface clock.
    0=I2C4 peripheral clocks disabled during CSleep mode; 1=I2C4 peripheral clocks enabled during CSleep mode (default after reset)
  [5] SPI6LPEN — SPI6 peripheral clocks enable during CSleep mode Set and reset by software. The peripheral clocks of the SPI6 are the kernel clock selected by SPI6SEL and provided to com_ck input, and the rcc_pclk4 bus interface clock.
    0=SPI6 peripheral clocks disabled during CSleep mode; 1=SPI6 peripheral clocks enabled during CSleep mode (default after reset)
  [3] LPUART1LPEN — LPUART1 peripheral clocks enable during CSleep mode Set and reset by software. The peripheral clocks of the LPUART1 are the kernel clock selected by LPUART1SEL and provided to lpuart_ker_ck input, and the rcc_pclk4 bus interface clock.
    0=LPUART1 peripheral clocks disabled during CSleep mode; 1=LPUART1 peripheral clocks enabled during CSleep mode (default after reset)
  [1] SYSCFGLPEN — SYSCFG peripheral clock enable during CSleep mode Set and reset by software.
    0=SYSCFG peripheral clock disabled during CSleep mode; 1=SYSCFG peripheral clock enabled during CSleep mode (default after reset)
